VERSION ""

NS_ :

BS_:

BU_:

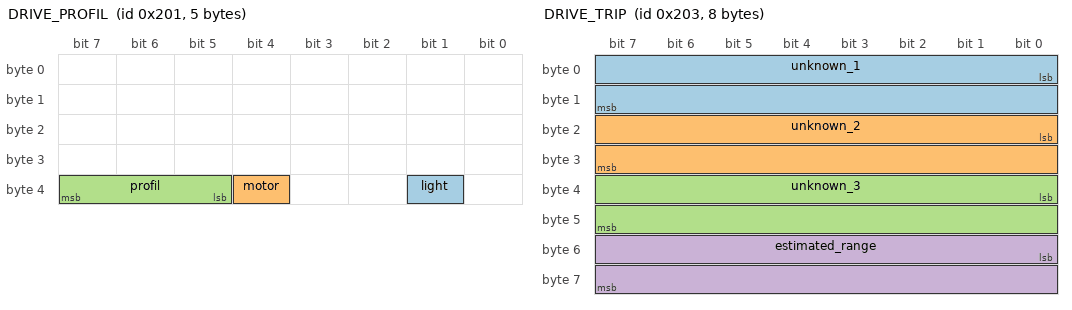
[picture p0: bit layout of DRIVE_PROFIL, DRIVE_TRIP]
BO_ 513 DRIVE_PROFIL: 5 Vector__XXX
    SG_ light : 33|1@1+ (1,0) [0|0] "" Vector__XXX
    SG_ motor : 36|1@1+ (1,0) [0|0] "" Vector__XXX
    SG_ profil : 37|3@1+ (1,0) [0|0] "" Vector__XXX

BO_ 514 DRIVE_ODO: 8 Vector__XXX
    SG_ unknown : 0|32@1+ (1,0) [0|0] "" Vector__XXX
    SG_ odometer : 32|32@1+ (0.001,0) [0|0] "km" Vector__XXX

BO_ 515 DRIVE_TRIP: 8 Vector__XXX
    SG_ unknown_1 : 0|16@1+ (1,0) [0|0] "" Vector__XXX
    SG_ unknown_2 : 16|16@1+ (1,0) [0|0] "" Vector__XXX
    SG_ unknown_3 : 32|16@1+ (1,0) [0|0] "" Vector__XXX
    SG_ estimated_range : 48|16@1+ (1,0) [0|0] "km" Vector__XXX

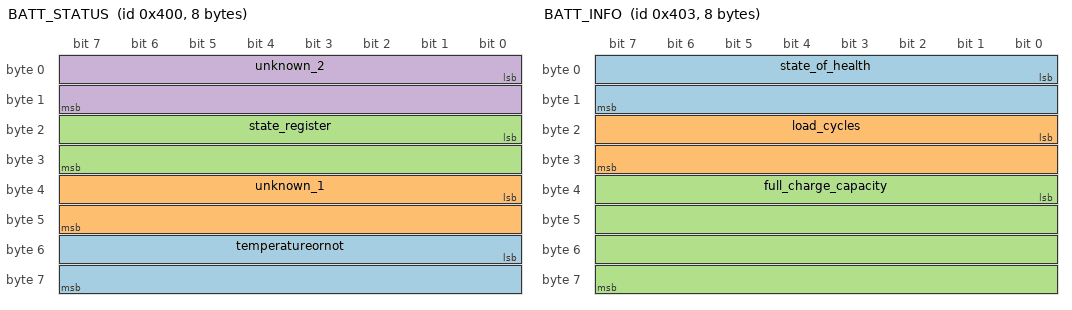
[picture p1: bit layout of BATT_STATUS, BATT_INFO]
BO_ 1024 BATT_STATUS: 8 Vector__XXX
    SG_ temperatureornot : 48|16@1+ (1,0) [0|0] "C" Vector__XXX
    SG_ unknown_1 : 32|16@1+ (1,0) [0|0] "" Vector__XXX
    SG_ state_register : 16|16@1+ (1,0) [0|0] "" Vector__XXX
    SG_ unknown_2 : 0|16@1+ (1,0) [0|0] "" Vector__XXX

BO_ 1025 BATT_POWER: 8 Vector__XXX
    SG_ actual_current : 32|32@1+ (0.001,0) [0|0] "A" Vector__XXX
    SG_ actual_voltage : 0|32@1- (0.001,0) [0|0] "V" Vector__XXX

BO_ 1026 BATT_CAPACITY: 8 Vector__XXX
    SG_ battery_level_relative : 0|32@1+ (1,0) [0|100] "%" Vector__XXX
    SG_ battery_level_absolute : 32|32@1+ (0.001,0) [0|0] "wh" Vector__XXX

BO_ 1027 BATT_INFO: 8 Vector__XXX
    SG_ state_of_health : 0|16@1+ (1,0) [0|100] "%" Vector__XXX
    SG_ load_cycles : 16|16@1+ (1,0) [0|100] "" Vector__XXX
    SG_ full_charge_capacity : 32|32@1+ (0.001,0) [0|0] "wh" Vector__XXX

CM_ BO_ 513 "Drive Unit profil";
CM_ SG_ 513 profil "mask: light : 0x02 - ";
CM_ BO_ 514 "Drive Unit Odometer";
CM_ BO_ 515 "Drive Unit Trip";
CM_ BO_ 1026 "Baterry capacity";
CM_ BO_ 1025 "Battery power";
CM_ BO_ 1024 "Battery status";
CM_ BO_ 1027 "Battery info";
BA_DEF_ BO_  "VFrameFormat" ENUM  "StandardCAN","ExtendedCAN","reserved","J1939PG";
BA_DEF_  "DatabaseVersion" STRING ;
BA_DEF_  "BusType" STRING ;
BA_DEF_  "ProtocolType" STRING ;
BA_DEF_  "DatabaseCompiler" STRING ;
BA_DEF_DEF_  "VFrameFormat" "J1939PG";
BA_DEF_DEF_  "DatabaseVersion" "DEMO PLUS";
BA_DEF_DEF_  "BusType" "";
BA_DEF_DEF_  "ProtocolType" "";
BA_DEF_DEF_  "DatabaseCompiler" "";
BA_ "ProtocolType" "J1939";
BA_ "BusType" "CAN";
BA_ "DatabaseCompiler" "CSS ELECTRONICS (WWW.CSSELECTRONICS.COM)";
BA_ "DatabaseVersion" "1.0.0";
